# PAC55XX register map
Vendor: Qorvo, Inc.; Series: PAC55XX; File version: 1.0
CPU: CM4 r0p1, little endian, MPU, FPU, vendor SysTick, 3 interrupt priority bits
Registers are 32-bit, read-write, reset 0x0 unless marked. A register's access mark holds for its fields unless they carry their own. Offsets are from the block's base; [hi:lo] are bit positions; {n}, {i} and the like mark numbered series; 'fields as' and 'values as' point back to an identical list.

## TIMERA
Base 0x40060000
Same registers: TIMERB 0x40070000, TIMERC 0x40080000, TIMERD 0x40090000
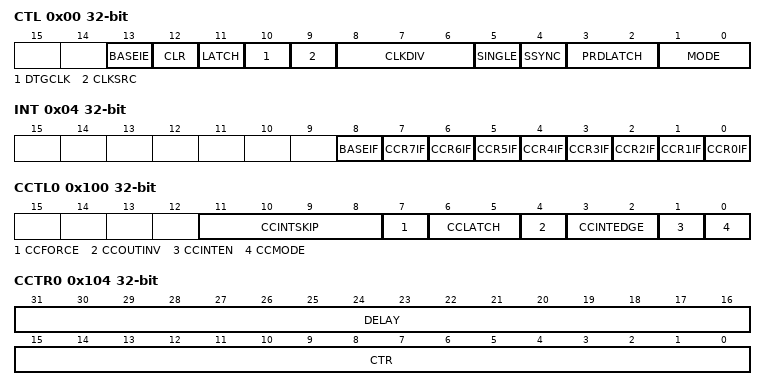
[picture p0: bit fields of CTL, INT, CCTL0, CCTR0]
0x00 CTL — Timer Control
  [13] BASEIE — Base timer interrupt enable
  [12] CLR — Timer Clear
  [11] LATCH — Write 1 to Latch Period and all CCTRs
  [10] DTGCLK — Dead-Time Generator Clock Source
    0=BEFORE_DIV (Before input clock divider); 1=AFTER_DIV (After input clock divider)
  [9] CLKSRC — Timer Clock Source
    0=PCLK (PCLK selected as input to timer); 1=ACLK (ACLK selected as input to timer)
  [8:6] CLKDIV — Timer Input Clock Divider
    0=DIV1 (Timer input clock /1); 1=DIV2 (Timer input clock /2); 2=DIV4 (Timer input clock /4); 3=DIV8 (Timer input clock /8); 4=DIV16 (Timer input clock /16); 5=DIV32 (Timer input clock /32); 6=DIV64 (Timer input clock /64); 7=DIV128 (Timer input clock /128)
  [5] SINGLE — Single Shot Timer
  [4] SSYNC — Timer Slave Synchronization
  [3:2] PRDLATCH — Timer Period Latch Mode
    0=CTR_0 (Period is latched when CTR = 0); 1=CTR_PERIOD (Period is latched when CTR = Period (PRD)); 2=IMMEDIATE (Period is latched immediately upon register write)
  [1:0] MODE — Timer Mode
    0=DISABLED; 1=UP (Up mode); 2=UP_DOWN (Up/Down mode); 3=ASYMMETRIC (Asymmetric mode)
0x04 INT — Timer Interrupt Control
  [8] BASEIF wo — Base Timer Interrupt Flag
  [n] CCR{n}IF wo (n=0..7) — CCR {n} Interrupt Flag
0x08 PRD — Timer Period
  [15:0] PRD — Timer Period Value
0x0C CTR — Timer Counter
  [15:0] COUNTER — Timer Counter Value
0x100 CCTL0 — Timer CCR Control
  [11:8] CCINTSKIP — CC Interrupt Skip Counter
    0=NONE (Don't skip CCR matches before interrupt); 1=SKIP1 (Skip 1 CCR match before interrupt); {v}=SKIP{v} (Skip {v} CCR matches before interrupt) (v=2..15)
  [7] CCFORCE — Write 1 to force compare event (self-clearing)
  [6:5] CCLATCH — CCR Register Latch Mode
    0=CTR_ZERO_OR_RISING_EDGE (Compare(latch on CTR=0)/ Capture(latch on rising edge)); 1=CTR_PERIOD_OR_FALLING_EDGE (Compare(latch on CTR=Period)/ Capture(latch on falling edge)); 2=IMMEDIATE_OR_BOTH_EDGES (Compare(latch immediately)/ Capture(latch on both edges))
  [4] CCOUTINV — Invert CCR Output
  [3:2] CCINTEDGE — Capture Mode Interrupt Edge Setting
    0=RISING (Rising Edge Interrupt); 1=FALLING (Falling Edge Interrupt); 2=BOTH (Rising and Falling Edge Interrupt)
  [1] CCINTEN — CCR Interrupt Enable
  [0] CCMODE — CCR Mode
    0=COMPARE (Compare Mode); 1=CAPTURE (Capture Mode)
0x104 CCTR0 — Timer CCR Counter
  [31:16] DELAY — Delay count to use before compare events
  [15:0] CTR — Capture/Compare value
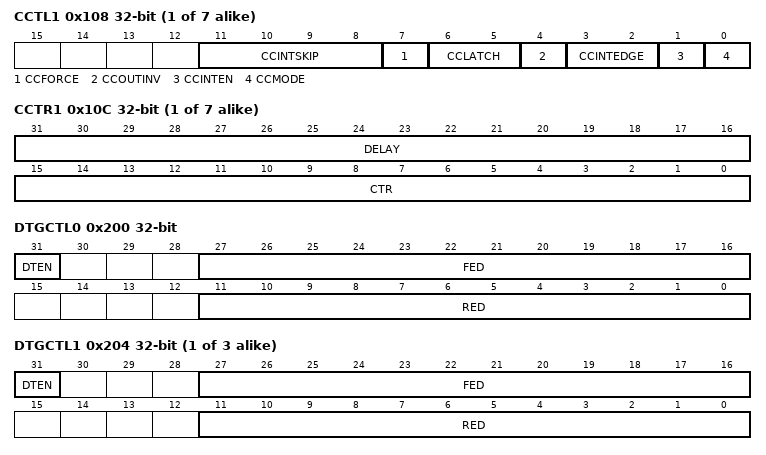
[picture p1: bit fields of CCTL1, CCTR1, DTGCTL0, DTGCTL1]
{0x100+8i} CCTL{i} (i=1..7) — Timer CCR Control {i}
  fields as CCTL0
{0x104+8i} CCTR{i} (i=1..7) — Timer CCR Counter {i}
  [31:16] DELAY — Delay count to use before compare events
  [15:0] CTR — Capture/Compare Value
0x200 DTGCTL0 — Timer Dead-Time Generator Control
  [31] DTEN — Dead-time generator enable
  [27:16] FED — Falling edge delay
  [11:0] RED — Rising edge delay
{0x200+4i} DTGCTL{i} (i=1..3) — Timer DTG Control {i}
  fields as DTGCTL0
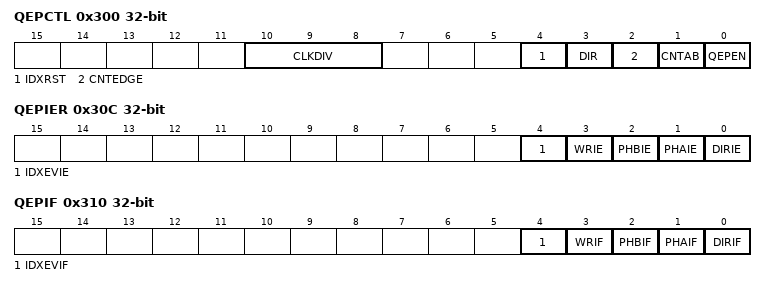
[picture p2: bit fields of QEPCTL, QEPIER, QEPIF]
0x300 QEPCTL — Timer QEP Control
  [10:8] CLKDIV — QEP input clock divider
  [4] IDXRST — Index reset
  [3] DIR — Motor direction
  [2] CNTEDGE — Count on edge
  [1] CNTAB — Count on A/B
  [0] QEPEN — QEP Enable
0x304 QEPCTR — Timer QEP Counter
  [31:0] CTR — Counter value
0x308 QEPMAX — Timer QEP Maximum Counter
  [31:0] CTRMAX — Maximum Counter value
0x30C QEPIER — Timer QEP Interrupt Enable
  [4] IDXEVIE — Index event interrupt enable
  [3] WRIE — Counter wrap interrupt enable
  [2] PHBIE — Phase B rising edge interrupt enable
  [1] PHAIE — Phase A rising edge interrupt enable
  [0] DIRIE — Direction change interrupt enable
0x310 QEPIF — Timer QEP Interrupt Enable
  [4] IDXEVIF — Index event interrupt flag
  [3] WRIF — Counter wrap interrupt flag
  [2] PHBIF — Phase B rising edge interrupt flag
  [1] PHAIF — Phase A rising edge interrupt flag
  [0] DIRIF — Direction change interrupt flag
